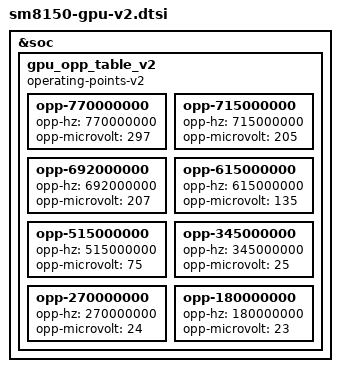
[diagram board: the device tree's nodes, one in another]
/* Copyright (c) 2018-2019, The Linux Foundation. All rights reserved.
 *
 * This program is free software; you can redistribute it and/or modify
 * it under the terms of the GNU General Public License version 2 and
 * only version 2 as published by the Free Software Foundation.
 *
 * This program is distributed in the hope that it will be useful,
 * but WITHOUT ANY WARRANTY; without even the implied warranty of
 * MERCHANTABILITY or FITNESS FOR A PARTICULAR PURPOSE.  See the
 * GNU General Public License for more details.
 */

&soc {
	gpu_opp_table_v2: gpu_opp_table_v2 {
		compatible = "operating-points-v2";

		opp-770000000 {
			opp-hz = /bits/ 64 <770000000>;
			opp-microvolt = <297>;
		};

		opp-715000000 {
			opp-hz = /bits/ 64 <715000000>;
			opp-microvolt = <205>;
		};

		opp-692000000 {
			opp-hz = /bits/ 64 <692000000>;
			opp-microvolt = <207>;
		};

		opp-615000000 {
			opp-hz = /bits/ 64 <615000000>;
			opp-microvolt = <135>;
		};

		opp-515000000 {
			opp-hz = /bits/ 64 <515000000>;
			opp-microvolt = <75>;
		};

		opp-345000000 {
			opp-hz = /bits/ 64 <345000000>;
			opp-microvolt = <25>;
		};

		opp-270000000 {
			opp-hz = /bits/ 64 <270000000>;
			opp-microvolt = <24>;
		};

		opp-180000000 {
			opp-hz = /bits/ 64 <180000000>;
			opp-microvolt = <23>;
		};
	};
};
